# EFM32TG1xx_2xx register map
File version: 2.7.3
CPU: CM3 r2p1, little endian, no MPU, no FPU, 3 interrupt priority bits
Registers are 32-bit, read-write, reset 0x0 unless marked. A register's access mark holds for its fields unless they carry their own. Offsets are from the block's base; [hi:lo] are bit positions; {n}, {i} and the like mark numbered series.

## EMU
Base 0x400C6000
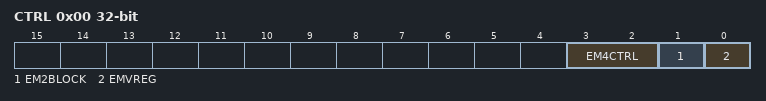
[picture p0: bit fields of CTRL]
0x00 CTRL — Control Register
  [3:2] EM4CTRL — Energy Mode 4 Control
  [1] EM2BLOCK — Energy Mode 2 Block
  [0] EMVREG — Energy Mode Voltage Regulator Control
0x08 LOCK — Configuration Lock Register
  [15:0] LOCKKEY — Configuration Lock Key
    0=UNLOCKED; 1=LOCKED
0x24 AUXCTRL — Auxiliary Control Register
  [0] HRCCLR — Hard Reset Cause Clear

## RMU
Base 0x400CA000
0x00 CTRL — Control Register
  [0] LOCKUPRDIS — Lockup Reset Disable
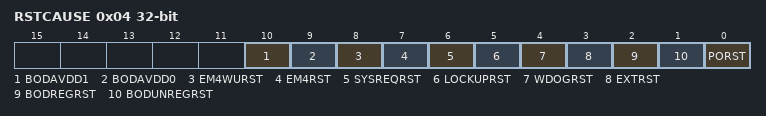
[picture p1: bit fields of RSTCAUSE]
0x04 RSTCAUSE ro — Reset Cause Register
  [10] BODAVDD1 — AVDD1 Bod Reset
  [9] BODAVDD0 — AVDD0 Bod Reset
  [8] EM4WURST — EM4 Wake-up Reset
  [7] EM4RST — EM4 Reset
  [6] SYSREQRST — System Request Reset
  [5] LOCKUPRST — LOCKUP Reset
  [4] WDOGRST — Watchdog Reset
  [3] EXTRST — External Pin Reset
  [2] BODREGRST — Brown Out Detector Regulated Domain Reset
  [1] BODUNREGRST — Brown Out Detector Unregulated Domain Reset
  [0] PORST — Power On Reset
0x08 CMD wo — Command Register
  [0] RCCLR — Reset Cause Clear

## RTC
Base 0x40080000
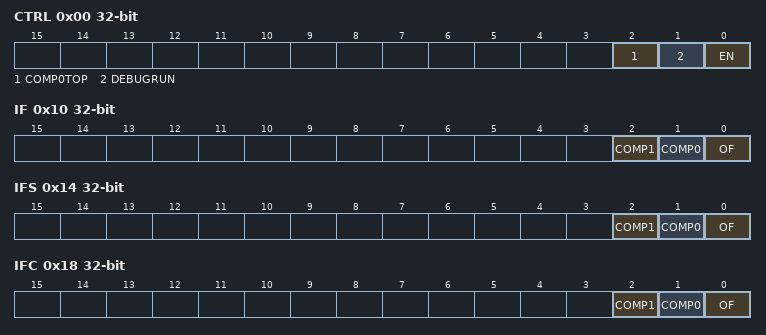
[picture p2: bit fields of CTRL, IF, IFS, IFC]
0x00 CTRL — Control Register
  [2] COMP0TOP — Compare Channel 0 is Top Value
  [1] DEBUGRUN — Debug Mode Run Enable
  [0] EN — RTC Enable
0x04 CNT — Counter Value Register
  [23:0] CNT — Counter Value
0x08 COMP0 — Compare Value Register 0
  [23:0] COMP0 — Compare Value 0
0x0C COMP1 — Compare Value Register 1
  [23:0] COMP1 — Compare Value 1
0x10 IF ro — Interrupt Flag Register
  [2] COMP1 — Compare Match 1 Interrupt Flag
  [1] COMP0 — Compare Match 0 Interrupt Flag
  [0] OF — Overflow Interrupt Flag
0x14 IFS wo — Interrupt Flag Set Register
  [2] COMP1 — Set Compare match 1 Interrupt Flag
  [1] COMP0 — Set Compare match 0 Interrupt Flag
  [0] OF — Set Overflow Interrupt Flag
0x18 IFC wo — Interrupt Flag Clear Register
  [2] COMP1 — Clear Compare match 1 Interrupt Flag
  [1] COMP0 — Clear Compare match 0 Interrupt Flag
  [0] OF — Clear Overflow Interrupt Flag
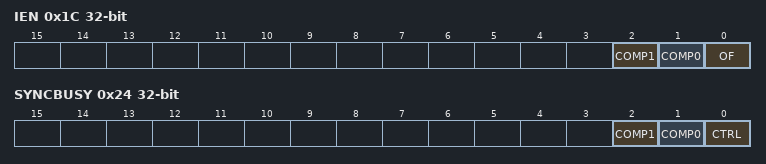
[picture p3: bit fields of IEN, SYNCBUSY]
0x1C IEN — Interrupt Enable Register
  [2] COMP1 — Compare Match 1 Interrupt Enable
  [1] COMP0 — Compare Match 0 Interrupt Enable
  [0] OF — Overflow Interrupt Enable
0x20 FREEZE
  [0] REGFREEZE — Register Update Freeze
0x24 SYNCBUSY ro — Synchronization Busy Register
  [2] COMP1 — COMP1 Register Busy
  [1] COMP0 — COMP0 Register Busy
  [0] CTRL — CTRL Register Busy

## ACMP0
Base 0x40001000
Same registers: ACMP1 0x40001400
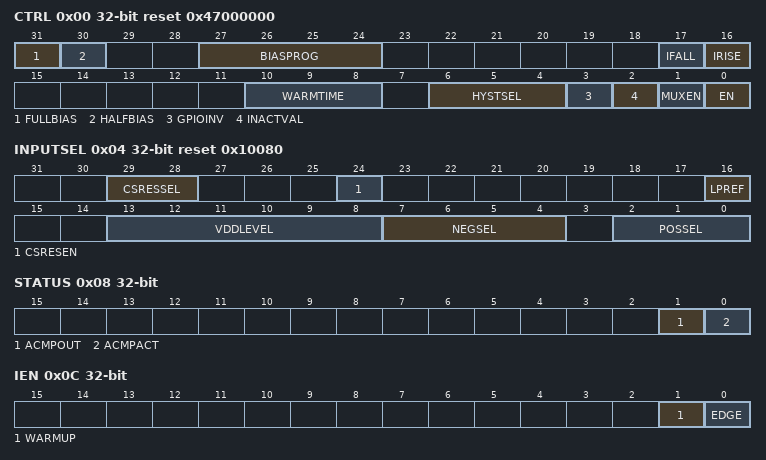
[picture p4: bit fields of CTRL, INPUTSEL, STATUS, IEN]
0x00 CTRL reset 0x47000000 — Control Register
  [31] FULLBIAS — Full Bias Current
  [30] HALFBIAS — Half Bias Current
  [27:24] BIASPROG — Bias Configuration
  [17] IFALL — Falling Edge Interrupt Sense
  [16] IRISE — Rising Edge Interrupt Sense
  [10:8] WARMTIME — Warm-up Time
    0=4CYCLES (4 HFPERCLK cycles.); 1=8CYCLES (8 HFPERCLK cycles.); 2=16CYCLES (16 HFPERCLK cycles.); 3=32CYCLES (32 HFPERCLK cycles.); 4=64CYCLES (64 HFPERCLK cycles.); 5=128CYCLES (128 HFPERCLK cycles.); 6=256CYCLES (256 HFPERCLK cycles.); 7=512CYCLES (512 HFPERCLK cycles.)
  [6:4] HYSTSEL — Hysteresis Select
    0=HYST0 (No hysteresis.); 1=HYST1 (~15 mV hysteresis.); 2=HYST2 (~22 mV hysteresis.); 3=HYST3 (~29 mV hysteresis.); 4=HYST4 (~36 mV hysteresis.); 5=HYST5 (~43 mV hysteresis.); 6=HYST6 (~50 mV hysteresis.); 7=HYST7 (~57 mV hysteresis.)
  [3] GPIOINV — Comparator GPIO Output Invert
  [2] INACTVAL — Inactive Value
  [1] MUXEN — Input Mux Enable
  [0] EN — Analog Comparator Enable
0x04 INPUTSEL reset 0x10080 — Input Selection Register
  [29:28] CSRESSEL — Capacitive Sense Mode Internal Resistor Select
    {v}=RES{v} (Internal capacitive sense resistor value {v}.) (v=0..3)
  [24] CSRESEN — Capacitive Sense Mode Internal Resistor Enable
  [16] LPREF — Low Power Reference Mode
  [13:8] VDDLEVEL — VDD Reference Level
  [7:4] NEGSEL — Negative Input Select
    {v}=CH{v} (Channel {v} as negative input.) (v=0..7); 8=1V25 (1.25 V as negative input.); 9=2V5 (2.5 V as negative input.); 10=VDD (Scaled VDD as negative input.); 11=CAPSENSE (Capacitive sense mode.); 12=DAC0CH0 (DAC0 channel 0.); 13=DAC0CH1 (DAC0 channel 1.)
  [2:0] POSSEL — Positive Input Select
    {v}=CH{v} (Channel {v} as positive input.) (v=0..7)
0x08 STATUS ro
  [1] ACMPOUT — Analog Comparator Output
  [0] ACMPACT — Analog Comparator Active
0x0C IEN — Interrupt Enable Register
  [1] WARMUP — Warm-up Interrupt Enable
  [0] EDGE — Edge Trigger Interrupt Enable
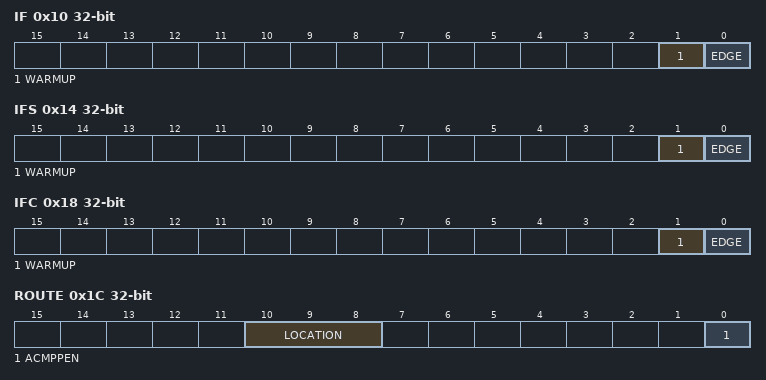
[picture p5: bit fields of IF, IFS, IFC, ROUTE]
0x10 IF ro — Interrupt Flag Register
  [1] WARMUP — Warm-up Interrupt Flag
  [0] EDGE — Edge Triggered Interrupt Flag
0x14 IFS wo — Interrupt Flag Set Register
  [1] WARMUP — Warm-up Interrupt Flag Set
  [0] EDGE — Edge Triggered Interrupt Flag Set
0x18 IFC wo — Interrupt Flag Clear Register
  [1] WARMUP — Warm-up Interrupt Flag Clear
  [0] EDGE — Edge Triggered Interrupt Flag Clear
0x1C ROUTE — I/O Routing Register
  [10:8] LOCATION — I/O Location
    0=LOC0 (Location 0); 1=LOC1 (Location 1); 2=LOC2 (Location 2)
  [0] ACMPPEN — ACMP Output Pin Enable

## Notices in the file
# License
Copyright 2020 Silicon Laboratories Inc. www.silabs.com
SPDX-License-Identifier: Zlib
The licensor of this software is Silicon Laboratories Inc.
This software is provided 'as-is', without any express or implied
warranty. In no event will the authors be held liable for any damages
arising from the use of this software.
Permission is granted to anyone to use this software for any purpose,
including commercial applications, and to alter it and redistribute it
freely, subject to the following restrictions:
1. The origin of this software must not be misrepresented; you must not
claim that you wrote the original software. If you use this software
in a product, an acknowledgment in the product documentation would be
appreciated but is not required.
2. Altered source versions must be plainly marked as such, and must not be
misrepresented as being the original software.
3. This notice may not be removed or altered from any source distribution.
